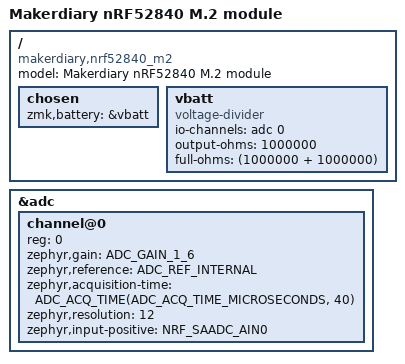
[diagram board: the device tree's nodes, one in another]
/*
 * Copyright (c) 2026 The ZMK Contributors
 *
 * SPDX-License-Identifier: MIT
 */

/dts-v1/;
#include <../boards/makerdiary/nrf52840_m2/nrf52840_m2.dts>
#include <common/nordic/nrf52840_uf2_boot_mode.dtsi>

/ {
    model = "Makerdiary nRF52840 M.2 module";
    compatible = "makerdiary,nrf52840_m2";

    chosen {
        zmk,battery = &vbatt;
    };

    vbatt: vbatt {
        compatible = "voltage-divider";
        io-channels = <&adc 0>;
        output-ohms = <1000000>;
        full-ohms = <(1000000 + 1000000)>;
    };
};

&adc {
    #address-cells = <1>;
    #size-cells = <0>;
    status = "okay";

    channel@0 {
        reg = <0>;
        zephyr,gain = "ADC_GAIN_1_6";
        zephyr,reference = "ADC_REF_INTERNAL";
        zephyr,acquisition-time = <ADC_ACQ_TIME(ADC_ACQ_TIME_MICROSECONDS, 40)>;
        zephyr,resolution = <12>;
        zephyr,input-positive = <NRF_SAADC_AIN0>;
    };
};
